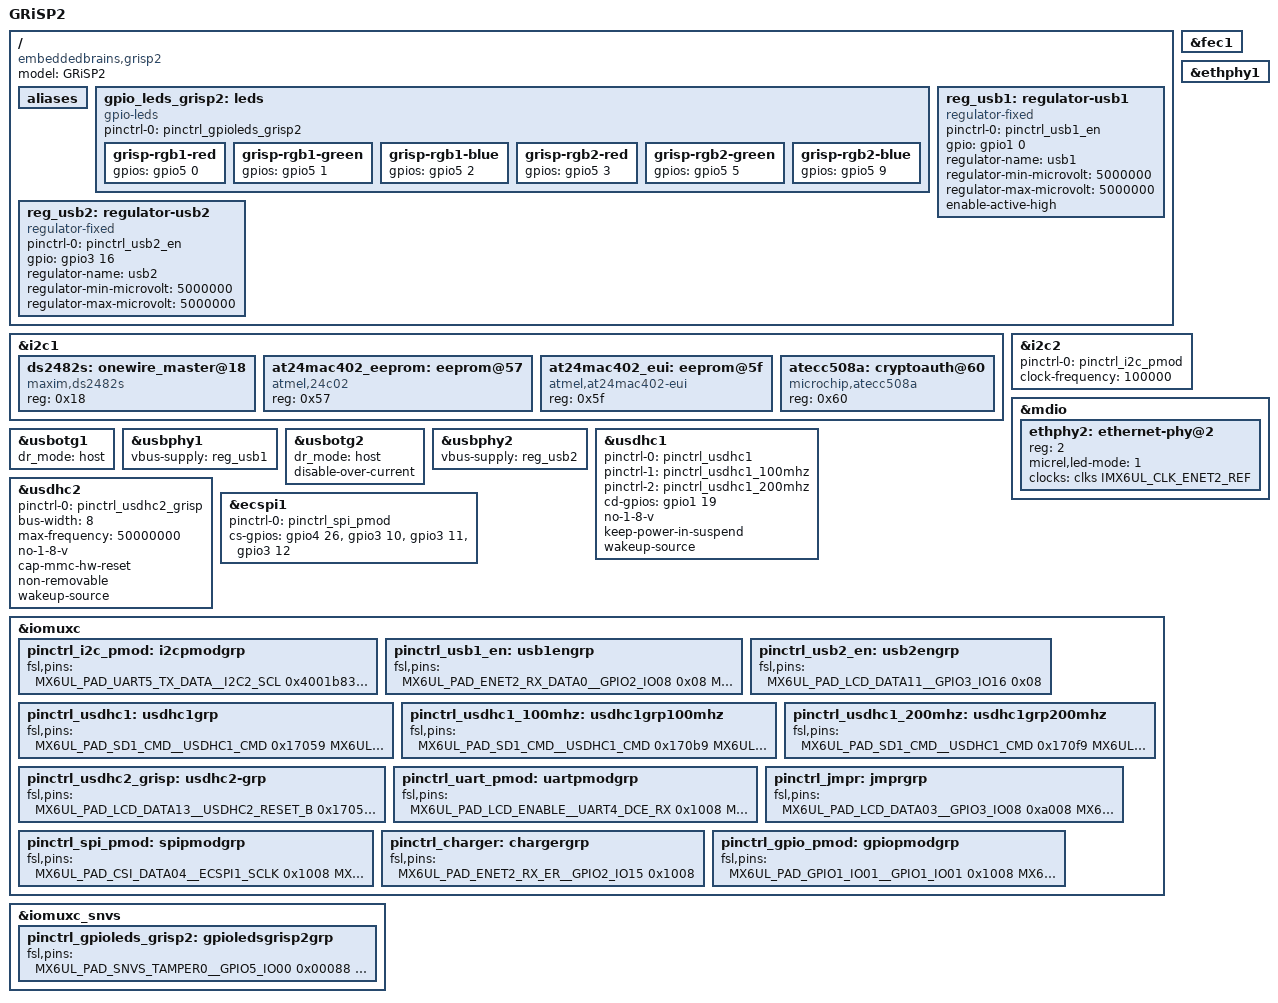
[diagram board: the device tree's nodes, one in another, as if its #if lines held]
// SPDX-License-Identifier: (GPL-2.0+ OR BSD-2-Clause)
/*
 * Copyright (C) 2020 embedded brains GmbH.
 */

#undef GRISP_IMX6ULL_Y0

/dts-v1/;
#include "imx6ull.dtsi"
#include "imx6ull-phytec-phycore-som.dtsi"

/ {
	model = "GRiSP2";
	compatible = "embeddedbrains,grisp2", "phytec,imx6ul-pbacd-10", "phytec,imx6ul-pcl063", "fsl,imx6ul";

	aliases {
#ifdef GRISP_IMX6ULL_Y0
		/delete-property/ serial4;
		/delete-property/ serial5;
		/delete-property/ serial6;
		/delete-property/ serial7;
		/delete-property/ usbphy1;
		/delete-property/ ethernet1;
#endif /* GRISP_IMX6ULL_Y0 */
	};

	gpio_leds_grisp2: leds {
		pinctrl-names = "default";
		pinctrl-0 = <&pinctrl_gpioleds_grisp2>;
		compatible = "gpio-leds";

		grisp-rgb1-red {
			gpios = <&gpio5 0 GPIO_ACTIVE_HIGH>;
		};
		grisp-rgb1-green {
			gpios = <&gpio5 1 GPIO_ACTIVE_HIGH>;
		};
		grisp-rgb1-blue {
			gpios = <&gpio5 2 GPIO_ACTIVE_HIGH>;
		};
		grisp-rgb2-red {
			gpios = <&gpio5 3 GPIO_ACTIVE_HIGH>;
		};
		grisp-rgb2-green {
			gpios = <&gpio5 5 GPIO_ACTIVE_HIGH>;
		};
		grisp-rgb2-blue {
			gpios = <&gpio5 9 GPIO_ACTIVE_HIGH>;
		};
	};

	reg_usb1: regulator-usb1 {
		compatible = "regulator-fixed";
		pinctrl-names = "default";
		pinctrl-0 = <&pinctrl_usb1_en>;
		gpio = <&gpio1 0 GPIO_ACTIVE_HIGH>;

		regulator-name = "usb1";
		regulator-min-microvolt = <5000000>;
		regulator-max-microvolt = <5000000>;
		enable-active-high;

		status = "okay";
	};

	reg_usb2: regulator-usb2 {
		compatible = "regulator-fixed";
		pinctrl-names = "default";
		pinctrl-0 = <&pinctrl_usb2_en>;
		gpio = <&gpio3 16 GPIO_ACTIVE_HIGH>;

		regulator-name = "usb2";
		regulator-min-microvolt = <5000000>;
		regulator-max-microvolt = <5000000>;

		status = "okay";
	};
};

#ifdef GRISP_IMX6ULL_Y0
/delete-node/ &uart5;
/delete-node/ &uart6;
/delete-node/ &uart7;
/delete-node/ &uart8;
/delete-node/ &usbphy2;
/delete-node/ &usbotg2;
/delete-node/ &fec2;
#endif /* GRISP_IMX6ULL_Y0 */

&fec1 {
	status = "okay";
};

&ethphy1 {
	status = "okay";
};

&i2c1 {
	status = "okay";

	ds2482s: onewire_master@18 {
		compatible = "maxim,ds2482s";
		reg = <0x18>;
		status = "okay";
	};
	at24mac402_eeprom: eeprom@57 {
		compatible = "atmel,24c02";
		reg = <0x57>;
		status = "okay";
	};
	at24mac402_eui: eeprom@5f {
		compatible = "atmel,at24mac402-eui";
		reg = <0x5f>;
		status = "okay";
	};
	atecc508a: cryptoauth@60 {
		compatible = "microchip,atecc508a", "atmel,at24c16";
		reg = <0x60>;
		status = "okay";
	};
};

&i2c2 {
	pinctrl-names = "default";
	pinctrl-0 = <&pinctrl_i2c_pmod>;
	clock-frequency = <100000>;
	status = "okay";
};

&mdio {
	ethphy2: ethernet-phy@2 {
		reg = <2>;
		micrel,led-mode = <1>;
		clocks = <&clks IMX6UL_CLK_ENET2_REF>;
		clock-names = "rmii-ref";
		status = "okay";
	};
};

&usbotg1 {
	pinctrl-names = "default";
	dr_mode = "host";
	status = "okay";
};

&usbphy1 {
#ifndef GRISP_IMX6ULL_Y0
	vbus-supply = <&reg_usb1>;
#else
	vbus-supply = <&reg_usb2>;
#endif
};

#ifndef GRISP_IMX6ULL_Y0
&usbotg2 {
	dr_mode = "host";
	disable-over-current;
	status = "okay";
};

&usbphy2 {
	vbus-supply = <&reg_usb2>;
};

#endif /* GRISP_IMX6ULL_Y0 */

&usdhc1 {
	pinctrl-names = "default", "state_100mhz", "state_200mhz";
	pinctrl-0 = <&pinctrl_usdhc1>;
	pinctrl-1 = <&pinctrl_usdhc1_100mhz>;
	pinctrl-2 = <&pinctrl_usdhc1_200mhz>;
	cd-gpios = <&gpio1 19 GPIO_ACTIVE_HIGH>;
	no-1-8-v;
	keep-power-in-suspend;
	wakeup-source;
	status = "okay";
};

&usdhc2 {
	pinctrl-names = "default";
#ifdef GRISP_IMX6ULL_Y0
	pinctrl-0 = <&pinctrl_usdhc2_grisp>;
	bus-width = <8>;
	max-frequency = <50000000>;
	no-1-8-v;
	cap-mmc-hw-reset;
#endif
	non-removable;
	wakeup-source;
	status = "okay";
};

&ecspi1 {
	status = "okay";
	pinctrl-0 = <&pinctrl_spi_pmod>;

	cs-gpios = <&gpio4 26 GPIO_ACTIVE_HIGH>,
		   <&gpio3 10 GPIO_ACTIVE_HIGH>,
		   <&gpio3 11 GPIO_ACTIVE_HIGH>,
		   <&gpio3 12 GPIO_ACTIVE_HIGH>;
};

&iomuxc {
	pinctrl_i2c_pmod: i2cpmodgrp {
		fsl,pins = <
			MX6UL_PAD_UART5_TX_DATA__I2C2_SCL	0x4001b830
			MX6UL_PAD_UART5_RX_DATA__I2C2_SDA	0x4001b830
			/* I2C_2_INT */
			MX6UL_PAD_GPIO1_IO08__GPIO1_IO08	0x1008
			/* I2C_2_RESET */
			MX6UL_PAD_GPIO1_IO09__GPIO1_IO09	0x1008
		>;
	};

	pinctrl_usb1_en: usb1engrp {
		fsl,pins = <
			/* USB_IF_1_EN */
			MX6UL_PAD_ENET2_RX_DATA0__GPIO2_IO08	0x08
			/* USB_IF_1_OC */
			MX6UL_PAD_ENET2_RX_DATA1__GPIO2_IO09	0x08
		>;
	};

	pinctrl_usb2_en: usb2engrp {
		fsl,pins = <
			/* WLAN_EN */
			MX6UL_PAD_LCD_DATA11__GPIO3_IO16	0x08
		>;
	};

	pinctrl_usdhc1: usdhc1grp {
		fsl,pins = <
			MX6UL_PAD_SD1_CMD__USDHC1_CMD		0x17059
			MX6UL_PAD_SD1_CLK__USDHC1_CLK		0x10059
			MX6UL_PAD_SD1_DATA0__USDHC1_DATA0	0x17059
			MX6UL_PAD_SD1_DATA1__USDHC1_DATA1	0x17059
			MX6UL_PAD_SD1_DATA2__USDHC1_DATA2	0x17059
			MX6UL_PAD_SD1_DATA3__USDHC1_DATA3	0x17059
			MX6UL_PAD_UART1_RTS_B__GPIO1_IO19	0x17059
		>;
	};

	pinctrl_usdhc1_100mhz: usdhc1grp100mhz {
		fsl,pins = <
			MX6UL_PAD_SD1_CMD__USDHC1_CMD		0x170b9
			MX6UL_PAD_SD1_CLK__USDHC1_CLK		0x100b9
			MX6UL_PAD_SD1_DATA0__USDHC1_DATA0	0x170b9
			MX6UL_PAD_SD1_DATA1__USDHC1_DATA1	0x170b9
			MX6UL_PAD_SD1_DATA2__USDHC1_DATA2	0x170b9
			MX6UL_PAD_SD1_DATA3__USDHC1_DATA3	0x170b9
			MX6UL_PAD_UART1_RTS_B__GPIO1_IO19	0x17059
		>;
	};

	pinctrl_usdhc1_200mhz: usdhc1grp200mhz {
		fsl,pins = <
			MX6UL_PAD_SD1_CMD__USDHC1_CMD		0x170f9
			MX6UL_PAD_SD1_CLK__USDHC1_CLK		0x100f9
			MX6UL_PAD_SD1_DATA0__USDHC1_DATA0	0x170f9
			MX6UL_PAD_SD1_DATA1__USDHC1_DATA1	0x170f9
			MX6UL_PAD_SD1_DATA2__USDHC1_DATA2	0x170f9
			MX6UL_PAD_SD1_DATA3__USDHC1_DATA3	0x170f9
			MX6UL_PAD_UART1_RTS_B__GPIO1_IO19	0x17059
		>;
	};

#ifdef GRISP_EXTERNAL_EMMC
	/delete-node/ pinctrl_usdhc2;

	pinctrl_usdhc2_grisp: usdhc2-grp {
		fsl,pins = <
			MX6UL_PAD_LCD_DATA13__USDHC2_RESET_B	0x17059
			MX6UL_PAD_LCD_DATA18__USDHC2_CMD	0x17059
			MX6UL_PAD_LCD_DATA19__USDHC2_CLK	0x17059
			MX6UL_PAD_LCD_DATA20__USDHC2_DATA0	0x17059
			MX6UL_PAD_LCD_DATA21__USDHC2_DATA1	0x17059
			MX6UL_PAD_LCD_DATA22__USDHC2_DATA2	0x17059
			MX6UL_PAD_LCD_DATA23__USDHC2_DATA3	0x17059
			MX6UL_PAD_LCD_DATA14__USDHC2_DATA4	0x17059
			MX6UL_PAD_LCD_DATA15__USDHC2_DATA5	0x17059
			MX6UL_PAD_LCD_DATA16__USDHC2_DATA6	0x17059
			MX6UL_PAD_LCD_DATA17__USDHC2_DATA7	0x17059
		>;
	};
#endif

	pinctrl_uart_pmod: uartpmodgrp {
		fsl,pins = <
			MX6UL_PAD_LCD_ENABLE__UART4_DCE_RX	0x1008
			MX6UL_PAD_LCD_CLK__UART4_DCE_TX		0x1008
			MX6UL_PAD_LCD_VSYNC__UART4_DCE_RTS	0x1008
			MX6UL_PAD_LCD_HSYNC__UART4_DCE_CTS	0x1008
			MX6UL_PAD_LCD_RESET__GPIO3_IO04		0x1008
			MX6UL_PAD_LCD_DATA00__GPIO3_IO05	0x1008
			MX6UL_PAD_LCD_DATA01__GPIO3_IO06	0x1008
			MX6UL_PAD_LCD_DATA02__GPIO3_IO07	0x1008
		>;
	};

	pinctrl_jmpr: jmprgrp {
		fsl,pins = <
			MX6UL_PAD_LCD_DATA03__GPIO3_IO08	0xa008
			MX6UL_PAD_LCD_DATA04__GPIO3_IO09	0xa008
			MX6UL_PAD_LCD_DATA08__GPIO3_IO13	0xa008
			MX6UL_PAD_LCD_DATA09__GPIO3_IO14	0xa008
			MX6UL_PAD_LCD_DATA10__GPIO3_IO15	0xa008
		>;
	};

	pinctrl_spi_pmod: spipmodgrp {
		fsl,pins = <
			MX6UL_PAD_CSI_DATA04__ECSPI1_SCLK	0x1008
			MX6UL_PAD_CSI_DATA06__ECSPI1_MOSI	0x1008
			MX6UL_PAD_CSI_DATA07__ECSPI1_MISO	0x3000
			/* SPI_SSx */
			MX6UL_PAD_CSI_DATA05__GPIO4_IO26	0x1008
			MX6UL_PAD_LCD_DATA05__GPIO3_IO10	0x1008
			MX6UL_PAD_LCD_DATA06__GPIO3_IO11	0x1008
			MX6UL_PAD_LCD_DATA07__GPIO3_IO12	0x1008
			/* SPI_RESET */
			MX6UL_PAD_CSI_DATA03__GPIO4_IO24	0x8
			/* SPI_INT */
			MX6UL_PAD_CSI_VSYNC__GPIO4_IO19		0x8
		>;
	};

	pinctrl_charger: chargergrp {
		fsl,pins = <
			/* CHARGER_IRQ */
			MX6UL_PAD_ENET2_RX_ER__GPIO2_IO15	0x1008
		>;
	};

	pinctrl_gpio_pmod: gpiopmodgrp {
		fsl,pins = <
			/* DIO1/AN1 */
			MX6UL_PAD_GPIO1_IO01__GPIO1_IO01	0x1008
			/* DIO2/AN2 */
			MX6UL_PAD_GPIO1_IO05__GPIO1_IO05	0x1008
			/* DIO3/AN3 */
			MX6UL_PAD_GPIO1_IO03__GPIO1_IO03	0x1008
			/* DIO4/AN4 */
			MX6UL_PAD_GPIO1_IO04__GPIO1_IO04	0x1008
			/* DIO5 */
			MX6UL_PAD_UART2_TX_DATA__GPIO1_IO20	0x1008
			/* DIO6 */
			MX6UL_PAD_UART2_RX_DATA__GPIO1_IO21	0x1008
			/* DIO7 */
			MX6UL_PAD_UART2_CTS_B__GPIO1_IO22	0x1008
			/* DIO8 */
			MX6UL_PAD_UART2_RTS_B__GPIO1_IO23	0x1008
		>;
	};
};

&iomuxc_snvs {
	pinctrl_gpioleds_grisp2: gpioledsgrisp2grp {
		fsl,pins = <
			MX6UL_PAD_SNVS_TAMPER0__GPIO5_IO00	0x00088
			MX6UL_PAD_SNVS_TAMPER1__GPIO5_IO01	0x00088
			MX6UL_PAD_SNVS_TAMPER2__GPIO5_IO02	0x00088
			MX6UL_PAD_SNVS_TAMPER3__GPIO5_IO03	0x00088
			MX6UL_PAD_SNVS_TAMPER5__GPIO5_IO05	0x00088
			MX6UL_PAD_SNVS_TAMPER9__GPIO5_IO09	0x00088
		>;
	};
};
